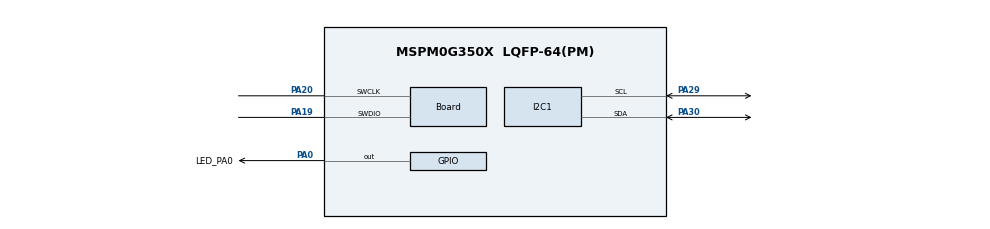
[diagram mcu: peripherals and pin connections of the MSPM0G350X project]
/**
 * @cliArgs --device "MSPM0G350X" --package "LQFP-64(PM)" --part "Default" --product "mspm0_sdk@2.00.01.00"
 * @versions {"tool":"1.20.0+3587"}
 */

/**
 * Import the modules used in this configuration.
 */
const GPIO          = scripting.addModule("/ti/driverlib/GPIO", {}, false);
const GPIO1         = GPIO.addInstance();
const I2C           = scripting.addModule("/ti/driverlib/I2C", {}, false);
const I2C1          = I2C.addInstance();
const PWM           = scripting.addModule("/ti/driverlib/PWM", {}, false);
const PWM1          = PWM.addInstance();
const PWM2          = PWM.addInstance();
const PWM3          = PWM.addInstance();
const PWM4          = PWM.addInstance();
const SYSCTL        = scripting.addModule("/ti/driverlib/SYSCTL");
const TIMER         = scripting.addModule("/ti/driverlib/TIMER", {}, false);
const TIMER1        = TIMER.addInstance();
const ProjectConfig = scripting.addModule("/ti/project_config/ProjectConfig");

/**
 * Write custom configuration values to the imported modules.
 */
GPIO1.port                          = "PORTA";
GPIO1.$name                         = "USER_GPIO";
GPIO1.associatedPins.create(9);
GPIO1.associatedPins[0].$name       = "LED_PA0";
GPIO1.associatedPins[0].pin.$assign = "PA0";
GPIO1.associatedPins[1].$name       = "PIN_A2";
GPIO1.associatedPins[2].$name       = "PIN_A1";
GPIO1.associatedPins[3].$name       = "PIN_B2";
GPIO1.associatedPins[4].$name       = "PIN_B1";
GPIO1.associatedPins[5].$name       = "PIN_C2";
GPIO1.associatedPins[6].$name       = "PIN_C1";
GPIO1.associatedPins[7].$name       = "PIN_D2";
GPIO1.associatedPins[8].$name       = "PIN_D1";

const Board                       = scripting.addModule("/ti/driverlib/Board", {}, false);
Board.peripheral.$assign          = "DEBUGSS";
Board.peripheral.swclkPin.$assign = "PA20";
Board.peripheral.swdioPin.$assign = "PA19";

I2C1.$name                     = "I2C_0";
I2C1.basicEnableController     = true;
I2C1.peripheral.$assign        = "I2C1";
I2C1.peripheral.sdaPin.$assign = "PA30";
I2C1.peripheral.sclPin.$assign = "PA29";
I2C1.sdaPinConfig.$name        = "ti_driverlib_gpio_GPIOPinGeneric0";
I2C1.sclPinConfig.$name        = "ti_driverlib_gpio_GPIOPinGeneric1";

PWM1.$name                              = "PWM_A";
PWM1.PWM_CHANNEL_0.$name                = "ti_driverlib_pwm_PWMTimerCC0";
PWM1.PWM_CHANNEL_1.$name                = "ti_driverlib_pwm_PWMTimerCC1";
PWM1.ccp0PinConfig.$name                = "ti_driverlib_gpio_GPIOPinGeneric2";
PWM1.ccp0PinConfig.direction            = scripting.forceWrite("OUTPUT");
PWM1.ccp0PinConfig.hideOutputInversion  = scripting.forceWrite(false);
PWM1.ccp0PinConfig.onlyInternalResistor = scripting.forceWrite(false);
PWM1.ccp0PinConfig.passedPeripheralType = scripting.forceWrite("Digital");
PWM1.ccp1PinConfig.$name                = "ti_driverlib_gpio_GPIOPinGeneric3";
PWM1.ccp1PinConfig.direction            = scripting.forceWrite("OUTPUT");
PWM1.ccp1PinConfig.hideOutputInversion  = scripting.forceWrite(false);
PWM1.ccp1PinConfig.onlyInternalResistor = scripting.forceWrite(false);
PWM1.ccp1PinConfig.passedPeripheralType = scripting.forceWrite("Digital");

PWM2.$name                              = "PWM_B";
PWM2.PWM_CHANNEL_0.$name                = "ti_driverlib_pwm_PWMTimerCC2";
PWM2.PWM_CHANNEL_1.$name                = "ti_driverlib_pwm_PWMTimerCC3";
PWM2.ccp0PinConfig.$name                = "ti_driverlib_gpio_GPIOPinGeneric4";
PWM2.ccp0PinConfig.direction            = scripting.forceWrite("OUTPUT");
PWM2.ccp0PinConfig.hideOutputInversion  = scripting.forceWrite(false);
PWM2.ccp0PinConfig.onlyInternalResistor = scripting.forceWrite(false);
PWM2.ccp0PinConfig.passedPeripheralType = scripting.forceWrite("Digital");
PWM2.ccp1PinConfig.$name                = "ti_driverlib_gpio_GPIOPinGeneric5";
PWM2.ccp1PinConfig.direction            = scripting.forceWrite("OUTPUT");
PWM2.ccp1PinConfig.hideOutputInversion  = scripting.forceWrite(false);
PWM2.ccp1PinConfig.onlyInternalResistor = scripting.forceWrite(false);
PWM2.ccp1PinConfig.passedPeripheralType = scripting.forceWrite("Digital");

PWM3.$name                              = "PWM_C";
PWM3.PWM_CHANNEL_0.$name                = "ti_driverlib_pwm_PWMTimerCC4";
PWM3.PWM_CHANNEL_1.$name                = "ti_driverlib_pwm_PWMTimerCC5";
PWM3.ccp0PinConfig.$name                = "ti_driverlib_gpio_GPIOPinGeneric6";
PWM3.ccp0PinConfig.direction            = scripting.forceWrite("OUTPUT");
PWM3.ccp0PinConfig.hideOutputInversion  = scripting.forceWrite(false);
PWM3.ccp0PinConfig.onlyInternalResistor = scripting.forceWrite(false);
PWM3.ccp0PinConfig.passedPeripheralType = scripting.forceWrite("Digital");
PWM3.ccp1PinConfig.$name                = "ti_driverlib_gpio_GPIOPinGeneric7";
PWM3.ccp1PinConfig.direction            = scripting.forceWrite("OUTPUT");
PWM3.ccp1PinConfig.hideOutputInversion  = scripting.forceWrite(false);
PWM3.ccp1PinConfig.onlyInternalResistor = scripting.forceWrite(false);
PWM3.ccp1PinConfig.passedPeripheralType = scripting.forceWrite("Digital");

PWM4.$name                              = "PWM_D";
PWM4.PWM_CHANNEL_0.$name                = "ti_driverlib_pwm_PWMTimerCC6";
PWM4.PWM_CHANNEL_1.$name                = "ti_driverlib_pwm_PWMTimerCC7";
PWM4.ccp0PinConfig.$name                = "ti_driverlib_gpio_GPIOPinGeneric8";
PWM4.ccp0PinConfig.direction            = scripting.forceWrite("OUTPUT");
PWM4.ccp0PinConfig.hideOutputInversion  = scripting.forceWrite(false);
PWM4.ccp0PinConfig.onlyInternalResistor = scripting.forceWrite(false);
PWM4.ccp0PinConfig.passedPeripheralType = scripting.forceWrite("Digital");
PWM4.ccp1PinConfig.$name                = "ti_driverlib_gpio_GPIOPinGeneric9";
PWM4.ccp1PinConfig.direction            = scripting.forceWrite("OUTPUT");
PWM4.ccp1PinConfig.hideOutputInversion  = scripting.forceWrite(false);
PWM4.ccp1PinConfig.onlyInternalResistor = scripting.forceWrite(false);
PWM4.ccp1PinConfig.passedPeripheralType = scripting.forceWrite("Digital");

SYSCTL.clockTreeEn = true;

TIMER1.$name              = "TIMER_0";
TIMER1.timerPeriod        = "100 ms";
TIMER1.timerClkPrescale   = 100;
TIMER1.timerMode          = "PERIODIC_UP";
TIMER1.interrupts         = ["ZERO"];
TIMER1.peripheral.$assign = "TIMG0";

ProjectConfig.deviceSpin = "MSPM0G3507";

/**
 * Pinmux solution for unlocked pins/peripherals. This ensures that minor changes to the automatic solver in a future
 * version of the tool will not impact the pinmux you originally saw.  These lines can be completely deleted in order to
 * re-solve from scratch.
 */
GPIO1.associatedPins[1].pin.$suggestSolution = "PA25";
GPIO1.associatedPins[2].pin.$suggestSolution = "PA24";
GPIO1.associatedPins[3].pin.$suggestSolution = "PA23";
GPIO1.associatedPins[4].pin.$suggestSolution = "PA16";
GPIO1.associatedPins[5].pin.$suggestSolution = "PA15";
GPIO1.associatedPins[6].pin.$suggestSolution = "PA14";
GPIO1.associatedPins[7].pin.$suggestSolution = "PA13";
GPIO1.associatedPins[8].pin.$suggestSolution = "PA12";
PWM1.peripheral.$suggestSolution             = "TIMG7";
PWM1.peripheral.ccp0Pin.$suggestSolution     = "PA17";
PWM1.peripheral.ccp1Pin.$suggestSolution     = "PA18";
PWM2.peripheral.$suggestSolution             = "TIMG6";
PWM2.peripheral.ccp0Pin.$suggestSolution     = "PA5";
PWM2.peripheral.ccp1Pin.$suggestSolution     = "PA22";
PWM3.peripheral.$suggestSolution             = "TIMA1";
PWM3.peripheral.ccp0Pin.$suggestSolution     = "PA10";
PWM3.peripheral.ccp1Pin.$suggestSolution     = "PA11";
PWM4.peripheral.$suggestSolution             = "TIMA0";
PWM4.peripheral.ccp0Pin.$suggestSolution     = "PA21";
PWM4.peripheral.ccp1Pin.$suggestSolution     = "PA1";
